CM_ "AUTOGENERATED FILE, DO NOT EDIT";

CM_ "honda_radar_scan.dbc starts here";
VERSION "honda_radar_scan -- Honda Bosch radar object scan: 16 object slots, each a POS/SHAPE/LIFE/IDENT frame quartet plus a synchronized MOTION companion. Raw counts only; physical conversion lives in iqdbc/car/honda/radar_scan.py"

NS_ :

BS_:

BU_: SCANNER XXX

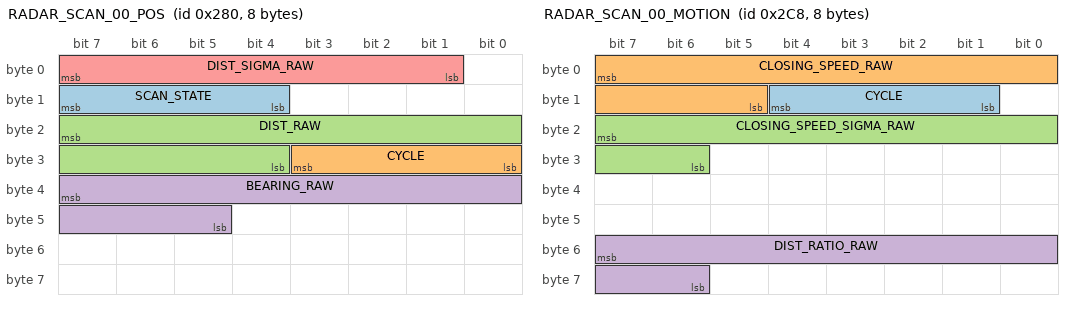
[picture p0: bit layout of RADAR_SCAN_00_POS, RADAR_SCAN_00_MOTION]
BO_ 640 RADAR_SCAN_00_POS: 8 SCANNER
 SG_ SCAN_STATE : 15|4@0+ (1,0) [0|15] "" XXX
 SG_ CYCLE : 27|4@0+ (1,0) [0|15] "" XXX
 SG_ DIST_RAW : 23|12@0+ (1,0) [0|4095] "" XXX
 SG_ BEARING_RAW : 39|11@0+ (1,0) [0|2047] "" XXX
 SG_ DIST_SIGMA_RAW : 7|7@0+ (1,0) [0|127] "" XXX

BO_ 641 RADAR_SCAN_00_SHAPE: 8 SCANNER
 SG_ CYCLE : 28|4@0+ (1,0) [0|15] "" XXX
 SG_ PRESENCE_RAW : 46|7@0+ (1,0) [0|127] "" XXX

BO_ 642 RADAR_SCAN_00_LIFE: 8 SCANNER
 SG_ CYCLE : 11|4@0+ (1,0) [0|15] "" XXX
 SG_ AGE_RAW : 7|12@0+ (1,0) [0|4095] "" XXX

BO_ 643 RADAR_SCAN_00_IDENT: 8 SCANNER
 SG_ CYCLE : 12|4@0+ (1,0) [0|15] "" XXX
 SG_ OBJECT_HANDLE : 55|8@0+ (1,0) [0|255] "" XXX

BO_ 712 RADAR_SCAN_00_MOTION: 8 SCANNER
 SG_ CYCLE : 12|4@0+ (1,0) [0|15] "" XXX
 SG_ CLOSING_SPEED_RAW : 7|11@0+ (1,0) [0|2047] "" XXX
 SG_ CLOSING_SPEED_SIGMA_RAW : 23|10@0+ (1,0) [0|1023] "" XXX
 SG_ DIST_RATIO_RAW : 55|10@0+ (1,0) [0|1023] "" XXX

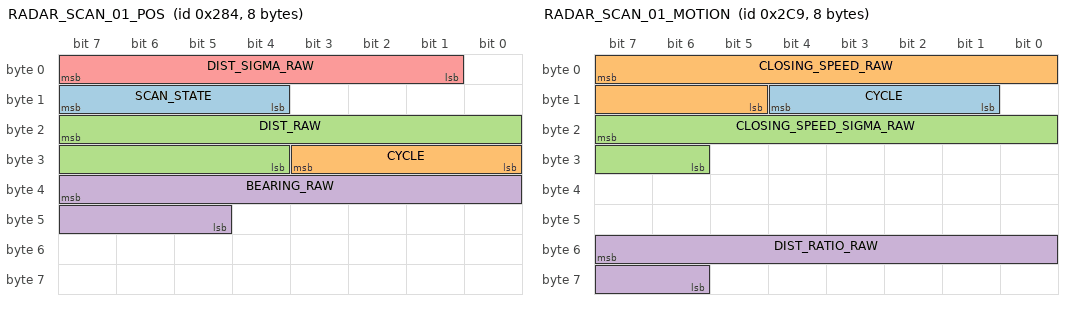
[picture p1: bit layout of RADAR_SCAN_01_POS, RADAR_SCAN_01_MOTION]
BO_ 644 RADAR_SCAN_01_POS: 8 SCANNER
 SG_ SCAN_STATE : 15|4@0+ (1,0) [0|15] "" XXX
 SG_ CYCLE : 27|4@0+ (1,0) [0|15] "" XXX
 SG_ DIST_RAW : 23|12@0+ (1,0) [0|4095] "" XXX
 SG_ BEARING_RAW : 39|11@0+ (1,0) [0|2047] "" XXX
 SG_ DIST_SIGMA_RAW : 7|7@0+ (1,0) [0|127] "" XXX

BO_ 645 RADAR_SCAN_01_SHAPE: 8 SCANNER
 SG_ CYCLE : 28|4@0+ (1,0) [0|15] "" XXX
 SG_ PRESENCE_RAW : 46|7@0+ (1,0) [0|127] "" XXX

BO_ 646 RADAR_SCAN_01_LIFE: 8 SCANNER
 SG_ CYCLE : 11|4@0+ (1,0) [0|15] "" XXX
 SG_ AGE_RAW : 7|12@0+ (1,0) [0|4095] "" XXX

BO_ 647 RADAR_SCAN_01_IDENT: 8 SCANNER
 SG_ CYCLE : 12|4@0+ (1,0) [0|15] "" XXX
 SG_ OBJECT_HANDLE : 55|8@0+ (1,0) [0|255] "" XXX

BO_ 713 RADAR_SCAN_01_MOTION: 8 SCANNER
 SG_ CYCLE : 12|4@0+ (1,0) [0|15] "" XXX
 SG_ CLOSING_SPEED_RAW : 7|11@0+ (1,0) [0|2047] "" XXX
 SG_ CLOSING_SPEED_SIGMA_RAW : 23|10@0+ (1,0) [0|1023] "" XXX
 SG_ DIST_RATIO_RAW : 55|10@0+ (1,0) [0|1023] "" XXX

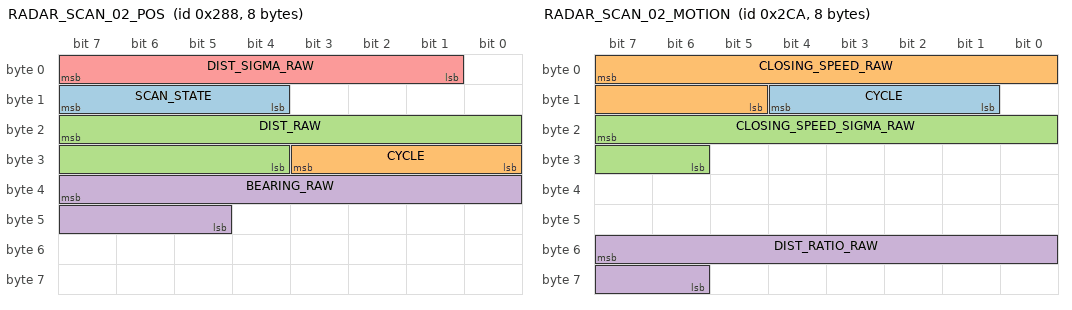
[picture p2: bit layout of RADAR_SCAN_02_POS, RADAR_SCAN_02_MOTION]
BO_ 648 RADAR_SCAN_02_POS: 8 SCANNER
 SG_ SCAN_STATE : 15|4@0+ (1,0) [0|15] "" XXX
 SG_ CYCLE : 27|4@0+ (1,0) [0|15] "" XXX
 SG_ DIST_RAW : 23|12@0+ (1,0) [0|4095] "" XXX
 SG_ BEARING_RAW : 39|11@0+ (1,0) [0|2047] "" XXX
 SG_ DIST_SIGMA_RAW : 7|7@0+ (1,0) [0|127] "" XXX

BO_ 649 RADAR_SCAN_02_SHAPE: 8 SCANNER
 SG_ CYCLE : 28|4@0+ (1,0) [0|15] "" XXX
 SG_ PRESENCE_RAW : 46|7@0+ (1,0) [0|127] "" XXX

BO_ 650 RADAR_SCAN_02_LIFE: 8 SCANNER
 SG_ CYCLE : 11|4@0+ (1,0) [0|15] "" XXX
 SG_ AGE_RAW : 7|12@0+ (1,0) [0|4095] "" XXX

BO_ 651 RADAR_SCAN_02_IDENT: 8 SCANNER
 SG_ CYCLE : 12|4@0+ (1,0) [0|15] "" XXX
 SG_ OBJECT_HANDLE : 55|8@0+ (1,0) [0|255] "" XXX

BO_ 714 RADAR_SCAN_02_MOTION: 8 SCANNER
 SG_ CYCLE : 12|4@0+ (1,0) [0|15] "" XXX
 SG_ CLOSING_SPEED_RAW : 7|11@0+ (1,0) [0|2047] "" XXX
 SG_ CLOSING_SPEED_SIGMA_RAW : 23|10@0+ (1,0) [0|1023] "" XXX
 SG_ DIST_RATIO_RAW : 55|10@0+ (1,0) [0|1023] "" XXX

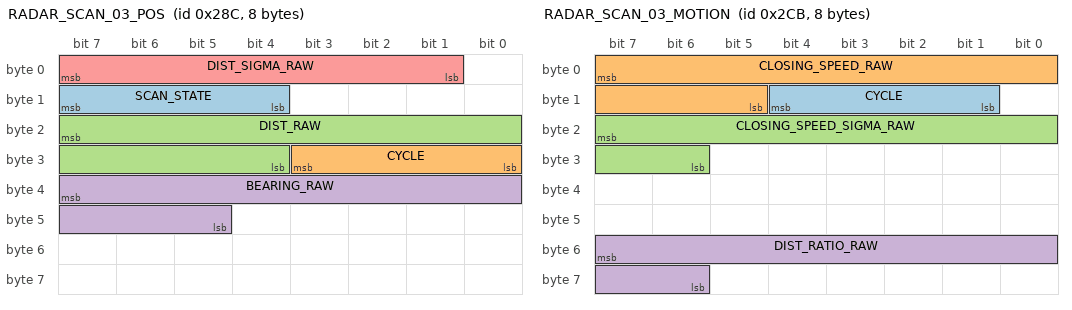
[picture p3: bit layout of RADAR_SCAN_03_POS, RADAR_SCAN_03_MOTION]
BO_ 652 RADAR_SCAN_03_POS: 8 SCANNER
 SG_ SCAN_STATE : 15|4@0+ (1,0) [0|15] "" XXX
 SG_ CYCLE : 27|4@0+ (1,0) [0|15] "" XXX
 SG_ DIST_RAW : 23|12@0+ (1,0) [0|4095] "" XXX
 SG_ BEARING_RAW : 39|11@0+ (1,0) [0|2047] "" XXX
 SG_ DIST_SIGMA_RAW : 7|7@0+ (1,0) [0|127] "" XXX

BO_ 653 RADAR_SCAN_03_SHAPE: 8 SCANNER
 SG_ CYCLE : 28|4@0+ (1,0) [0|15] "" XXX
 SG_ PRESENCE_RAW : 46|7@0+ (1,0) [0|127] "" XXX

BO_ 654 RADAR_SCAN_03_LIFE: 8 SCANNER
 SG_ CYCLE : 11|4@0+ (1,0) [0|15] "" XXX
 SG_ AGE_RAW : 7|12@0+ (1,0) [0|4095] "" XXX

BO_ 655 RADAR_SCAN_03_IDENT: 8 SCANNER
 SG_ CYCLE : 12|4@0+ (1,0) [0|15] "" XXX
 SG_ OBJECT_HANDLE : 55|8@0+ (1,0) [0|255] "" XXX

BO_ 715 RADAR_SCAN_03_MOTION: 8 SCANNER
 SG_ CYCLE : 12|4@0+ (1,0) [0|15] "" XXX
 SG_ CLOSING_SPEED_RAW : 7|11@0+ (1,0) [0|2047] "" XXX
 SG_ CLOSING_SPEED_SIGMA_RAW : 23|10@0+ (1,0) [0|1023] "" XXX
 SG_ DIST_RATIO_RAW : 55|10@0+ (1,0) [0|1023] "" XXX

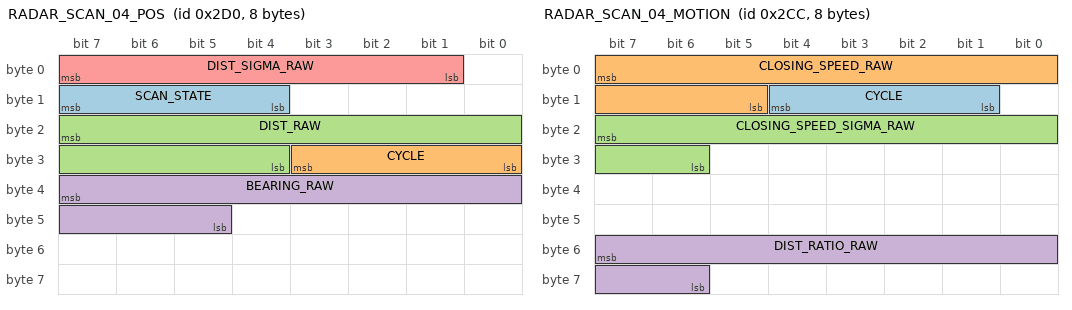
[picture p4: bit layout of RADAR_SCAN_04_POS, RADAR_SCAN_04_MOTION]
BO_ 720 RADAR_SCAN_04_POS: 8 SCANNER
 SG_ SCAN_STATE : 15|4@0+ (1,0) [0|15] "" XXX
 SG_ CYCLE : 27|4@0+ (1,0) [0|15] "" XXX
 SG_ DIST_RAW : 23|12@0+ (1,0) [0|4095] "" XXX
 SG_ BEARING_RAW : 39|11@0+ (1,0) [0|2047] "" XXX
 SG_ DIST_SIGMA_RAW : 7|7@0+ (1,0) [0|127] "" XXX

BO_ 721 RADAR_SCAN_04_SHAPE: 8 SCANNER
 SG_ CYCLE : 28|4@0+ (1,0) [0|15] "" XXX
 SG_ PRESENCE_RAW : 46|7@0+ (1,0) [0|127] "" XXX

BO_ 722 RADAR_SCAN_04_LIFE: 8 SCANNER
 SG_ CYCLE : 11|4@0+ (1,0) [0|15] "" XXX
 SG_ AGE_RAW : 7|12@0+ (1,0) [0|4095] "" XXX

BO_ 723 RADAR_SCAN_04_IDENT: 8 SCANNER
 SG_ CYCLE : 12|4@0+ (1,0) [0|15] "" XXX
 SG_ OBJECT_HANDLE : 55|8@0+ (1,0) [0|255] "" XXX

BO_ 716 RADAR_SCAN_04_MOTION: 8 SCANNER
 SG_ CYCLE : 12|4@0+ (1,0) [0|15] "" XXX
 SG_ CLOSING_SPEED_RAW : 7|11@0+ (1,0) [0|2047] "" XXX
 SG_ CLOSING_SPEED_SIGMA_RAW : 23|10@0+ (1,0) [0|1023] "" XXX
 SG_ DIST_RATIO_RAW : 55|10@0+ (1,0) [0|1023] "" XXX

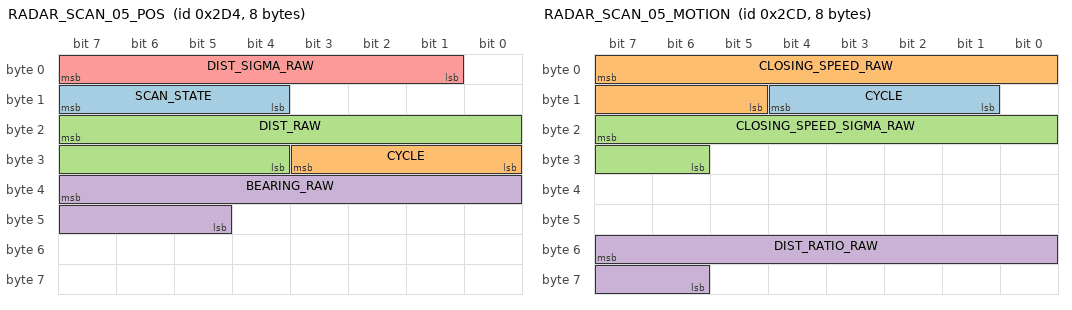
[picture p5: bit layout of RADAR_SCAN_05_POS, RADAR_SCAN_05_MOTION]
BO_ 724 RADAR_SCAN_05_POS: 8 SCANNER
 SG_ SCAN_STATE : 15|4@0+ (1,0) [0|15] "" XXX
 SG_ CYCLE : 27|4@0+ (1,0) [0|15] "" XXX
 SG_ DIST_RAW : 23|12@0+ (1,0) [0|4095] "" XXX
 SG_ BEARING_RAW : 39|11@0+ (1,0) [0|2047] "" XXX
 SG_ DIST_SIGMA_RAW : 7|7@0+ (1,0) [0|127] "" XXX

BO_ 725 RADAR_SCAN_05_SHAPE: 8 SCANNER
 SG_ CYCLE : 28|4@0+ (1,0) [0|15] "" XXX
 SG_ PRESENCE_RAW : 46|7@0+ (1,0) [0|127] "" XXX

BO_ 726 RADAR_SCAN_05_LIFE: 8 SCANNER
 SG_ CYCLE : 11|4@0+ (1,0) [0|15] "" XXX
 SG_ AGE_RAW : 7|12@0+ (1,0) [0|4095] "" XXX

BO_ 727 RADAR_SCAN_05_IDENT: 8 SCANNER
 SG_ CYCLE : 12|4@0+ (1,0) [0|15] "" XXX
 SG_ OBJECT_HANDLE : 55|8@0+ (1,0) [0|255] "" XXX

BO_ 717 RADAR_SCAN_05_MOTION: 8 SCANNER
 SG_ CYCLE : 12|4@0+ (1,0) [0|15] "" XXX
 SG_ CLOSING_SPEED_RAW : 7|11@0+ (1,0) [0|2047] "" XXX
 SG_ CLOSING_SPEED_SIGMA_RAW : 23|10@0+ (1,0) [0|1023] "" XXX
 SG_ DIST_RATIO_RAW : 55|10@0+ (1,0) [0|1023] "" XXX

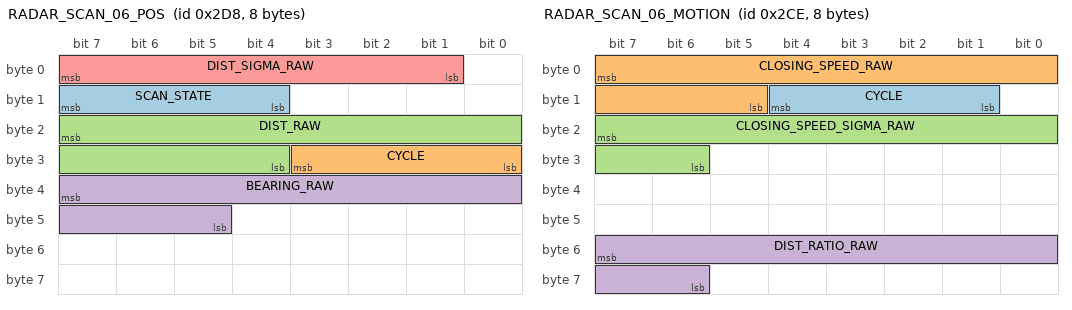
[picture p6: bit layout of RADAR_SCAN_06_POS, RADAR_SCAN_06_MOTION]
BO_ 728 RADAR_SCAN_06_POS: 8 SCANNER
 SG_ SCAN_STATE : 15|4@0+ (1,0) [0|15] "" XXX
 SG_ CYCLE : 27|4@0+ (1,0) [0|15] "" XXX
 SG_ DIST_RAW : 23|12@0+ (1,0) [0|4095] "" XXX
 SG_ BEARING_RAW : 39|11@0+ (1,0) [0|2047] "" XXX
 SG_ DIST_SIGMA_RAW : 7|7@0+ (1,0) [0|127] "" XXX

BO_ 729 RADAR_SCAN_06_SHAPE: 8 SCANNER
 SG_ CYCLE : 28|4@0+ (1,0) [0|15] "" XXX
 SG_ PRESENCE_RAW : 46|7@0+ (1,0) [0|127] "" XXX

BO_ 730 RADAR_SCAN_06_LIFE: 8 SCANNER
 SG_ CYCLE : 11|4@0+ (1,0) [0|15] "" XXX
 SG_ AGE_RAW : 7|12@0+ (1,0) [0|4095] "" XXX

BO_ 731 RADAR_SCAN_06_IDENT: 8 SCANNER
 SG_ CYCLE : 12|4@0+ (1,0) [0|15] "" XXX
 SG_ OBJECT_HANDLE : 55|8@0+ (1,0) [0|255] "" XXX

BO_ 718 RADAR_SCAN_06_MOTION: 8 SCANNER
 SG_ CYCLE : 12|4@0+ (1,0) [0|15] "" XXX
 SG_ CLOSING_SPEED_RAW : 7|11@0+ (1,0) [0|2047] "" XXX
 SG_ CLOSING_SPEED_SIGMA_RAW : 23|10@0+ (1,0) [0|1023] "" XXX
 SG_ DIST_RATIO_RAW : 55|10@0+ (1,0) [0|1023] "" XXX

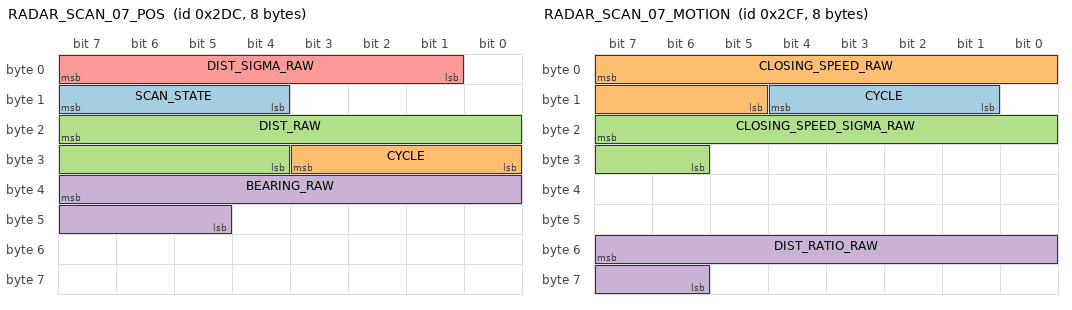
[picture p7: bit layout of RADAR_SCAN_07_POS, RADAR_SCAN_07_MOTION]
BO_ 732 RADAR_SCAN_07_POS: 8 SCANNER
 SG_ SCAN_STATE : 15|4@0+ (1,0) [0|15] "" XXX
 SG_ CYCLE : 27|4@0+ (1,0) [0|15] "" XXX
 SG_ DIST_RAW : 23|12@0+ (1,0) [0|4095] "" XXX
 SG_ BEARING_RAW : 39|11@0+ (1,0) [0|2047] "" XXX
 SG_ DIST_SIGMA_RAW : 7|7@0+ (1,0) [0|127] "" XXX

BO_ 733 RADAR_SCAN_07_SHAPE: 8 SCANNER
 SG_ CYCLE : 28|4@0+ (1,0) [0|15] "" XXX
 SG_ PRESENCE_RAW : 46|7@0+ (1,0) [0|127] "" XXX

BO_ 734 RADAR_SCAN_07_LIFE: 8 SCANNER
 SG_ CYCLE : 11|4@0+ (1,0) [0|15] "" XXX
 SG_ AGE_RAW : 7|12@0+ (1,0) [0|4095] "" XXX

BO_ 735 RADAR_SCAN_07_IDENT: 8 SCANNER
 SG_ CYCLE : 12|4@0+ (1,0) [0|15] "" XXX
 SG_ OBJECT_HANDLE : 55|8@0+ (1,0) [0|255] "" XXX

BO_ 719 RADAR_SCAN_07_MOTION: 8 SCANNER
 SG_ CYCLE : 12|4@0+ (1,0) [0|15] "" XXX
 SG_ CLOSING_SPEED_RAW : 7|11@0+ (1,0) [0|2047] "" XXX
 SG_ CLOSING_SPEED_SIGMA_RAW : 23|10@0+ (1,0) [0|1023] "" XXX
 SG_ DIST_RATIO_RAW : 55|10@0+ (1,0) [0|1023] "" XXX

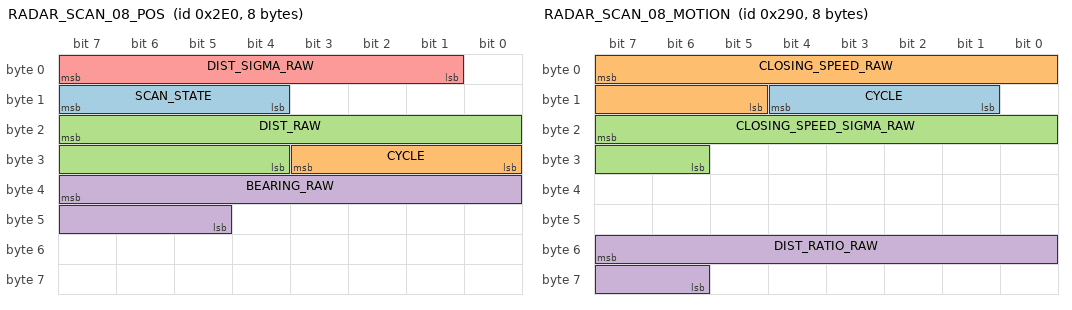
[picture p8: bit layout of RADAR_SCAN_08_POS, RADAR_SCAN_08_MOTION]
BO_ 736 RADAR_SCAN_08_POS: 8 SCANNER
 SG_ SCAN_STATE : 15|4@0+ (1,0) [0|15] "" XXX
 SG_ CYCLE : 27|4@0+ (1,0) [0|15] "" XXX
 SG_ DIST_RAW : 23|12@0+ (1,0) [0|4095] "" XXX
 SG_ BEARING_RAW : 39|11@0+ (1,0) [0|2047] "" XXX
 SG_ DIST_SIGMA_RAW : 7|7@0+ (1,0) [0|127] "" XXX

BO_ 737 RADAR_SCAN_08_SHAPE: 8 SCANNER
 SG_ CYCLE : 28|4@0+ (1,0) [0|15] "" XXX
 SG_ PRESENCE_RAW : 46|7@0+ (1,0) [0|127] "" XXX

BO_ 738 RADAR_SCAN_08_LIFE: 8 SCANNER
 SG_ CYCLE : 11|4@0+ (1,0) [0|15] "" XXX
 SG_ AGE_RAW : 7|12@0+ (1,0) [0|4095] "" XXX

BO_ 739 RADAR_SCAN_08_IDENT: 8 SCANNER
 SG_ CYCLE : 12|4@0+ (1,0) [0|15] "" XXX
 SG_ OBJECT_HANDLE : 55|8@0+ (1,0) [0|255] "" XXX

BO_ 656 RADAR_SCAN_08_MOTION: 8 SCANNER
 SG_ CYCLE : 12|4@0+ (1,0) [0|15] "" XXX
 SG_ CLOSING_SPEED_RAW : 7|11@0+ (1,0) [0|2047] "" XXX
 SG_ CLOSING_SPEED_SIGMA_RAW : 23|10@0+ (1,0) [0|1023] "" XXX
 SG_ DIST_RATIO_RAW : 55|10@0+ (1,0) [0|1023] "" XXX

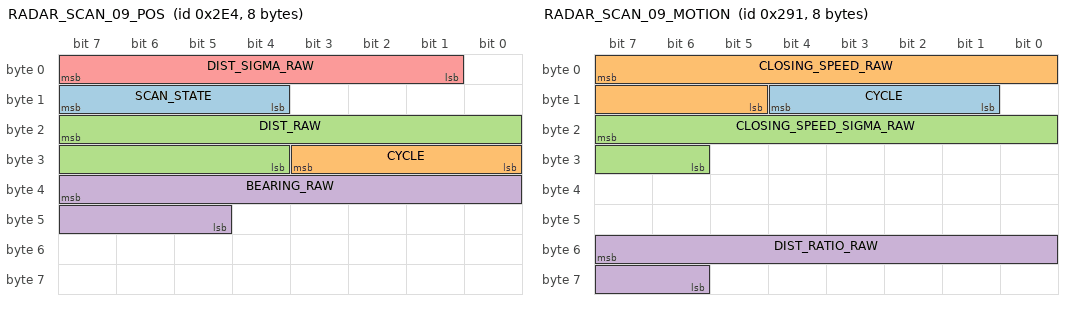
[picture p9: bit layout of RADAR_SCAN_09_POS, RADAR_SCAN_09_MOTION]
BO_ 740 RADAR_SCAN_09_POS: 8 SCANNER
 SG_ SCAN_STATE : 15|4@0+ (1,0) [0|15] "" XXX
 SG_ CYCLE : 27|4@0+ (1,0) [0|15] "" XXX
 SG_ DIST_RAW : 23|12@0+ (1,0) [0|4095] "" XXX
 SG_ BEARING_RAW : 39|11@0+ (1,0) [0|2047] "" XXX
 SG_ DIST_SIGMA_RAW : 7|7@0+ (1,0) [0|127] "" XXX

BO_ 741 RADAR_SCAN_09_SHAPE: 8 SCANNER
 SG_ CYCLE : 28|4@0+ (1,0) [0|15] "" XXX
 SG_ PRESENCE_RAW : 46|7@0+ (1,0) [0|127] "" XXX

BO_ 742 RADAR_SCAN_09_LIFE: 8 SCANNER
 SG_ CYCLE : 11|4@0+ (1,0) [0|15] "" XXX
 SG_ AGE_RAW : 7|12@0+ (1,0) [0|4095] "" XXX

BO_ 743 RADAR_SCAN_09_IDENT: 8 SCANNER
 SG_ CYCLE : 12|4@0+ (1,0) [0|15] "" XXX
 SG_ OBJECT_HANDLE : 55|8@0+ (1,0) [0|255] "" XXX

BO_ 657 RADAR_SCAN_09_MOTION: 8 SCANNER
 SG_ CYCLE : 12|4@0+ (1,0) [0|15] "" XXX
 SG_ CLOSING_SPEED_RAW : 7|11@0+ (1,0) [0|2047] "" XXX
 SG_ CLOSING_SPEED_SIGMA_RAW : 23|10@0+ (1,0) [0|1023] "" XXX
 SG_ DIST_RATIO_RAW : 55|10@0+ (1,0) [0|1023] "" XXX

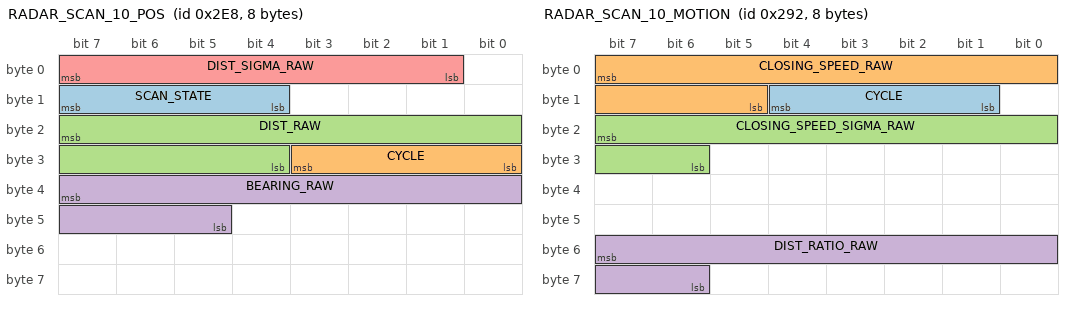
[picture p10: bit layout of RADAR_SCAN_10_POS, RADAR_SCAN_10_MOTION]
BO_ 744 RADAR_SCAN_10_POS: 8 SCANNER
 SG_ SCAN_STATE : 15|4@0+ (1,0) [0|15] "" XXX
 SG_ CYCLE : 27|4@0+ (1,0) [0|15] "" XXX
 SG_ DIST_RAW : 23|12@0+ (1,0) [0|4095] "" XXX
 SG_ BEARING_RAW : 39|11@0+ (1,0) [0|2047] "" XXX
 SG_ DIST_SIGMA_RAW : 7|7@0+ (1,0) [0|127] "" XXX

BO_ 745 RADAR_SCAN_10_SHAPE: 8 SCANNER
 SG_ CYCLE : 28|4@0+ (1,0) [0|15] "" XXX
 SG_ PRESENCE_RAW : 46|7@0+ (1,0) [0|127] "" XXX

BO_ 746 RADAR_SCAN_10_LIFE: 8 SCANNER
 SG_ CYCLE : 11|4@0+ (1,0) [0|15] "" XXX
 SG_ AGE_RAW : 7|12@0+ (1,0) [0|4095] "" XXX

BO_ 747 RADAR_SCAN_10_IDENT: 8 SCANNER
 SG_ CYCLE : 12|4@0+ (1,0) [0|15] "" XXX
 SG_ OBJECT_HANDLE : 55|8@0+ (1,0) [0|255] "" XXX

BO_ 658 RADAR_SCAN_10_MOTION: 8 SCANNER
 SG_ CYCLE : 12|4@0+ (1,0) [0|15] "" XXX
 SG_ CLOSING_SPEED_RAW : 7|11@0+ (1,0) [0|2047] "" XXX
 SG_ CLOSING_SPEED_SIGMA_RAW : 23|10@0+ (1,0) [0|1023] "" XXX
 SG_ DIST_RATIO_RAW : 55|10@0+ (1,0) [0|1023] "" XXX

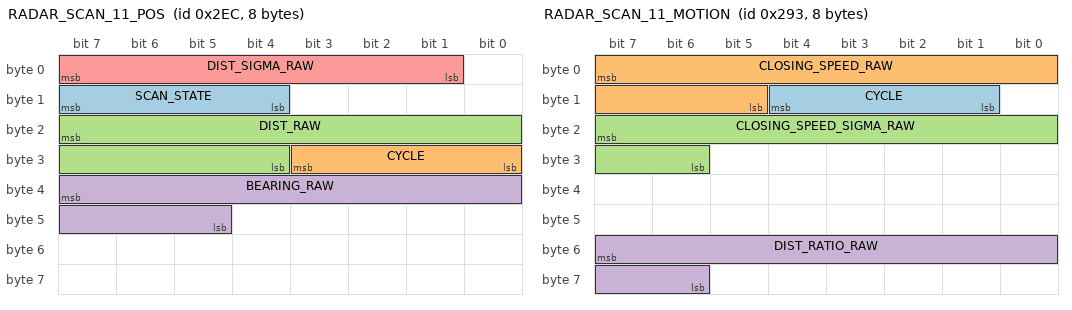
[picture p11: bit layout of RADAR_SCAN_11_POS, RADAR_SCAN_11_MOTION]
BO_ 748 RADAR_SCAN_11_POS: 8 SCANNER
 SG_ SCAN_STATE : 15|4@0+ (1,0) [0|15] "" XXX
 SG_ CYCLE : 27|4@0+ (1,0) [0|15] "" XXX
 SG_ DIST_RAW : 23|12@0+ (1,0) [0|4095] "" XXX
 SG_ BEARING_RAW : 39|11@0+ (1,0) [0|2047] "" XXX
 SG_ DIST_SIGMA_RAW : 7|7@0+ (1,0) [0|127] "" XXX

BO_ 749 RADAR_SCAN_11_SHAPE: 8 SCANNER
 SG_ CYCLE : 28|4@0+ (1,0) [0|15] "" XXX
 SG_ PRESENCE_RAW : 46|7@0+ (1,0) [0|127] "" XXX

BO_ 750 RADAR_SCAN_11_LIFE: 8 SCANNER
 SG_ CYCLE : 11|4@0+ (1,0) [0|15] "" XXX
 SG_ AGE_RAW : 7|12@0+ (1,0) [0|4095] "" XXX

BO_ 751 RADAR_SCAN_11_IDENT: 8 SCANNER
 SG_ CYCLE : 12|4@0+ (1,0) [0|15] "" XXX
 SG_ OBJECT_HANDLE : 55|8@0+ (1,0) [0|255] "" XXX

BO_ 659 RADAR_SCAN_11_MOTION: 8 SCANNER
 SG_ CYCLE : 12|4@0+ (1,0) [0|15] "" XXX
 SG_ CLOSING_SPEED_RAW : 7|11@0+ (1,0) [0|2047] "" XXX
 SG_ CLOSING_SPEED_SIGMA_RAW : 23|10@0+ (1,0) [0|1023] "" XXX
 SG_ DIST_RATIO_RAW : 55|10@0+ (1,0) [0|1023] "" XXX

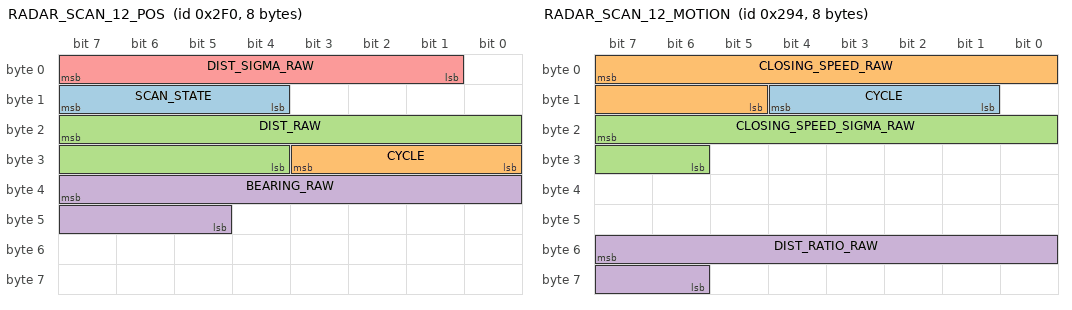
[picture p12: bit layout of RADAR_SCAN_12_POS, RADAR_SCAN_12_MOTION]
BO_ 752 RADAR_SCAN_12_POS: 8 SCANNER
 SG_ SCAN_STATE : 15|4@0+ (1,0) [0|15] "" XXX
 SG_ CYCLE : 27|4@0+ (1,0) [0|15] "" XXX
 SG_ DIST_RAW : 23|12@0+ (1,0) [0|4095] "" XXX
 SG_ BEARING_RAW : 39|11@0+ (1,0) [0|2047] "" XXX
 SG_ DIST_SIGMA_RAW : 7|7@0+ (1,0) [0|127] "" XXX

BO_ 753 RADAR_SCAN_12_SHAPE: 8 SCANNER
 SG_ CYCLE : 28|4@0+ (1,0) [0|15] "" XXX
 SG_ PRESENCE_RAW : 46|7@0+ (1,0) [0|127] "" XXX

BO_ 754 RADAR_SCAN_12_LIFE: 8 SCANNER
 SG_ CYCLE : 11|4@0+ (1,0) [0|15] "" XXX
 SG_ AGE_RAW : 7|12@0+ (1,0) [0|4095] "" XXX

BO_ 755 RADAR_SCAN_12_IDENT: 8 SCANNER
 SG_ CYCLE : 12|4@0+ (1,0) [0|15] "" XXX
 SG_ OBJECT_HANDLE : 55|8@0+ (1,0) [0|255] "" XXX

BO_ 660 RADAR_SCAN_12_MOTION: 8 SCANNER
 SG_ CYCLE : 12|4@0+ (1,0) [0|15] "" XXX
 SG_ CLOSING_SPEED_RAW : 7|11@0+ (1,0) [0|2047] "" XXX
 SG_ CLOSING_SPEED_SIGMA_RAW : 23|10@0+ (1,0) [0|1023] "" XXX
 SG_ DIST_RATIO_RAW : 55|10@0+ (1,0) [0|1023] "" XXX

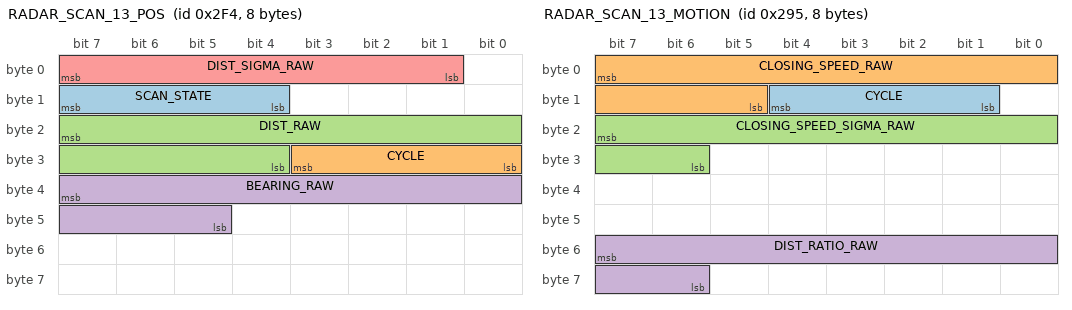
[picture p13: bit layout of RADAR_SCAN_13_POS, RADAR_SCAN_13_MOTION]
BO_ 756 RADAR_SCAN_13_POS: 8 SCANNER
 SG_ SCAN_STATE : 15|4@0+ (1,0) [0|15] "" XXX
 SG_ CYCLE : 27|4@0+ (1,0) [0|15] "" XXX
 SG_ DIST_RAW : 23|12@0+ (1,0) [0|4095] "" XXX
 SG_ BEARING_RAW : 39|11@0+ (1,0) [0|2047] "" XXX
 SG_ DIST_SIGMA_RAW : 7|7@0+ (1,0) [0|127] "" XXX

BO_ 757 RADAR_SCAN_13_SHAPE: 8 SCANNER
 SG_ CYCLE : 28|4@0+ (1,0) [0|15] "" XXX
 SG_ PRESENCE_RAW : 46|7@0+ (1,0) [0|127] "" XXX

BO_ 758 RADAR_SCAN_13_LIFE: 8 SCANNER
 SG_ CYCLE : 11|4@0+ (1,0) [0|15] "" XXX
 SG_ AGE_RAW : 7|12@0+ (1,0) [0|4095] "" XXX

BO_ 759 RADAR_SCAN_13_IDENT: 8 SCANNER
 SG_ CYCLE : 12|4@0+ (1,0) [0|15] "" XXX
 SG_ OBJECT_HANDLE : 55|8@0+ (1,0) [0|255] "" XXX

BO_ 661 RADAR_SCAN_13_MOTION: 8 SCANNER
 SG_ CYCLE : 12|4@0+ (1,0) [0|15] "" XXX
 SG_ CLOSING_SPEED_RAW : 7|11@0+ (1,0) [0|2047] "" XXX
 SG_ CLOSING_SPEED_SIGMA_RAW : 23|10@0+ (1,0) [0|1023] "" XXX
 SG_ DIST_RATIO_RAW : 55|10@0+ (1,0) [0|1023] "" XXX

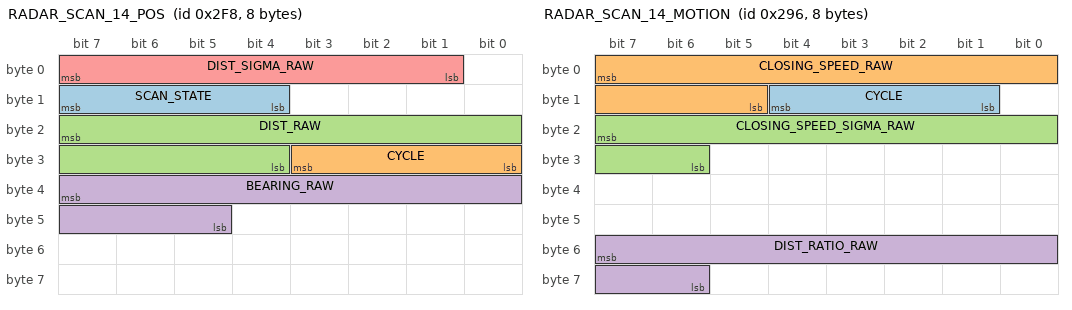
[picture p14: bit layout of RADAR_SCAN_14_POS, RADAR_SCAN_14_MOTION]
BO_ 760 RADAR_SCAN_14_POS: 8 SCANNER
 SG_ SCAN_STATE : 15|4@0+ (1,0) [0|15] "" XXX
 SG_ CYCLE : 27|4@0+ (1,0) [0|15] "" XXX
 SG_ DIST_RAW : 23|12@0+ (1,0) [0|4095] "" XXX
 SG_ BEARING_RAW : 39|11@0+ (1,0) [0|2047] "" XXX
 SG_ DIST_SIGMA_RAW : 7|7@0+ (1,0) [0|127] "" XXX

BO_ 761 RADAR_SCAN_14_SHAPE: 8 SCANNER
 SG_ CYCLE : 28|4@0+ (1,0) [0|15] "" XXX
 SG_ PRESENCE_RAW : 46|7@0+ (1,0) [0|127] "" XXX

BO_ 762 RADAR_SCAN_14_LIFE: 8 SCANNER
 SG_ CYCLE : 11|4@0+ (1,0) [0|15] "" XXX
 SG_ AGE_RAW : 7|12@0+ (1,0) [0|4095] "" XXX

BO_ 763 RADAR_SCAN_14_IDENT: 8 SCANNER
 SG_ CYCLE : 12|4@0+ (1,0) [0|15] "" XXX
 SG_ OBJECT_HANDLE : 55|8@0+ (1,0) [0|255] "" XXX

BO_ 662 RADAR_SCAN_14_MOTION: 8 SCANNER
 SG_ CYCLE : 12|4@0+ (1,0) [0|15] "" XXX
 SG_ CLOSING_SPEED_RAW : 7|11@0+ (1,0) [0|2047] "" XXX
 SG_ CLOSING_SPEED_SIGMA_RAW : 23|10@0+ (1,0) [0|1023] "" XXX
 SG_ DIST_RATIO_RAW : 55|10@0+ (1,0) [0|1023] "" XXX

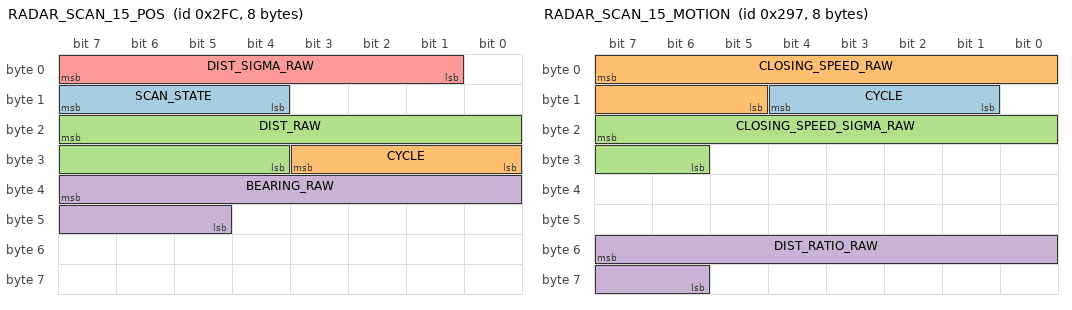
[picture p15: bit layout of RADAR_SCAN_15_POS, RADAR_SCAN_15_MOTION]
BO_ 764 RADAR_SCAN_15_POS: 8 SCANNER
 SG_ SCAN_STATE : 15|4@0+ (1,0) [0|15] "" XXX
 SG_ CYCLE : 27|4@0+ (1,0) [0|15] "" XXX
 SG_ DIST_RAW : 23|12@0+ (1,0) [0|4095] "" XXX
 SG_ BEARING_RAW : 39|11@0+ (1,0) [0|2047] "" XXX
 SG_ DIST_SIGMA_RAW : 7|7@0+ (1,0) [0|127] "" XXX

BO_ 765 RADAR_SCAN_15_SHAPE: 8 SCANNER
 SG_ CYCLE : 28|4@0+ (1,0) [0|15] "" XXX
 SG_ PRESENCE_RAW : 46|7@0+ (1,0) [0|127] "" XXX

BO_ 766 RADAR_SCAN_15_LIFE: 8 SCANNER
 SG_ CYCLE : 11|4@0+ (1,0) [0|15] "" XXX
 SG_ AGE_RAW : 7|12@0+ (1,0) [0|4095] "" XXX

BO_ 767 RADAR_SCAN_15_IDENT: 8 SCANNER
 SG_ CYCLE : 12|4@0+ (1,0) [0|15] "" XXX
 SG_ OBJECT_HANDLE : 55|8@0+ (1,0) [0|255] "" XXX

BO_ 663 RADAR_SCAN_15_MOTION: 8 SCANNER
 SG_ CYCLE : 12|4@0+ (1,0) [0|15] "" XXX
 SG_ CLOSING_SPEED_RAW : 7|11@0+ (1,0) [0|2047] "" XXX
 SG_ CLOSING_SPEED_SIGMA_RAW : 23|10@0+ (1,0) [0|1023] "" XXX
 SG_ DIST_RATIO_RAW : 55|10@0+ (1,0) [0|1023] "" XXX
